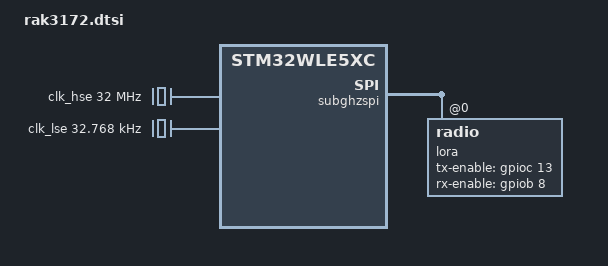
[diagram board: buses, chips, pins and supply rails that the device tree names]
/*
 * Copyright (c) 2024 Teslabs Engineering S.L.
 * SPDX-License-Identifier: Apache-2.0
 */

#include <st/wl/stm32wle5Xc.dtsi>
#include <st/wl/stm32wle5ccux-pinctrl.dtsi>

&clk_hse {
	clock-frequency = <DT_FREQ_M(32)>;
	status = "okay";
};

&clk_lse {
	clock-frequency = <32768>;
	status = "okay";
};

&subghzspi {
	status = "okay";

	lora: radio@0 {
		tx-enable-gpios = <&gpioc 13 GPIO_ACTIVE_HIGH>; /* FE_CTRL1 */
		rx-enable-gpios = <&gpiob 8 GPIO_ACTIVE_HIGH>;  /* FE_CTRL2 */
		power-amplifier-output = "rfo-hp";
		rfo-hp-max-power = <22>;
		status = "okay";
	};
};
